# ATBTLC1000WLCSP register map
Vendor: Atmel Corp; Series: SAMB11; File version: TODO
CPU: CM0 r0p0, little endian, no MPU, no FPU, 2 interrupt priority bits
Address unit: 32 bits
Registers are 32-bit, read-write, reset 0x0 unless marked. A register's access mark holds for its fields unless they carry their own. Offsets are from the block's base; [hi:lo] are bit positions; {n}, {i} and the like mark numbered series; 'fields as' and 'values as' point back to an identical list.

## SPI_FLASH0 — SPI Flash Controller
Base 0x40012000
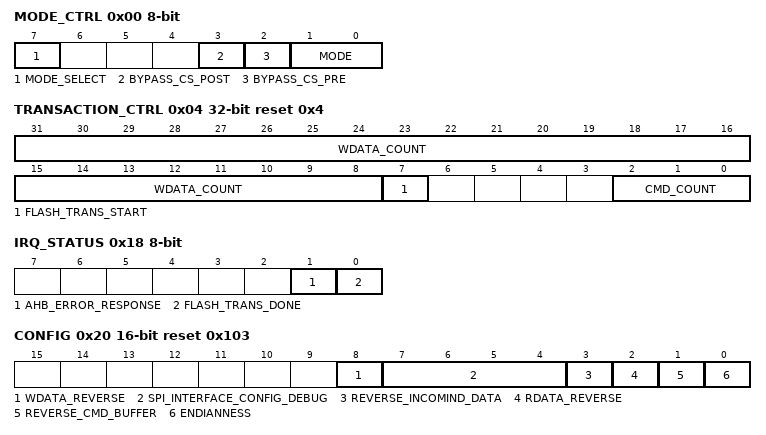
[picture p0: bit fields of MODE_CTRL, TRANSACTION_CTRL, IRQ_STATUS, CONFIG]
0x00 MODE_CTRL 8-bit — SPI Flash Mode Control
  [7] MODE_SELECT — Set to 1 to use external bits for mode
  [3] BYPASS_CS_POST — Bypass CS POST state
  [2] BYPASS_CS_PRE — Bypass CS PRE state
  [1:0] MODE — SPI Modes
    {v}=Mode {v} (v=0..3)
0x04 TRANSACTION_CTRL reset 0x4 — Transaction Control (Cleared after each transaction completes)
  [31:8] WDATA_COUNT — Number of bytes to be programmed to flash
  [7] FLASH_TRANS_START — Rising Edge Flast Transaction Start
  [2:0] CMD_COUNT — Number of bytes to be transferred or received
0x08 READ_CTRL — Read Control (Cleared after each transaction completes)
  [23:0] RDATA_COUNT — Number of data bytes to be read from flash
0x0C CMD_BUFFER0 reset 0x3 — Command Buffer 0 (Bytes 3 - 0)
0x10 CMD_BUFFER1 — Command Buffer 1 (Bytes 7 - 4)
0x14 DIRECTION 8-bit reset 0xF — Read/Write bit for Bytes 7 - 0
0x18 IRQ_STATUS 8-bit wo — IRQ Status (Write 0 to bit to clear, Read clears interupts)
  [1] AHB_ERROR_RESPONSE
  [0] FLASH_TRANS_DONE — Current Flash Transaction Done
0x1C DMA_START_ADDRESS — DMA Starting Address
0x20 CONFIG 16-bit reset 0x103 — SPI Flash Configuration
  [8] WDATA_REVERSE — Reverse bits of every data byte written to flash
  [7:4] SPI_INTERFACE_CONFIG_DEBUG — Debug only
  [3] REVERSE_INCOMIND_DATA — Reverse bits of status registers read from flash
  [2] RDATA_REVERSE — Reverse bits of every data byte read from flash
  [1] REVERSE_CMD_BUFFER — Reverse bits of every byte in cmd_buffer
  [0] ENDIANNESS — 1 for Little Endian
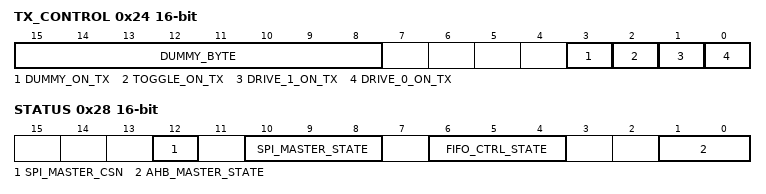
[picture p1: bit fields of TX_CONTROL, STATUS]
0x24 TX_CONTROL 16-bit
  [15:8] DUMMY_BYTE — Byte to be sent for dummy_on_tx option
  [3] DUMMY_ON_TX — Send dummy_byte while reading
  [2] TOGGLE_ON_TX — Toggle TX while reading
  [1] DRIVE_1_ON_TX — Drive 1 on TX while reading
  [0] DRIVE_0_ON_TX — Drive 0 on TX while reading
0x28 STATUS 16-bit ro — Misc Status
  [12] SPI_MASTER_CSN — Inverted version of the SPI Master Chip Select
  [10:8] SPI_MASTER_STATE
    0=IDLE; 1=READ; 2=WRITE; 3=READ_FLASH; 4=WRITE_FLASH; 5=PRE_ACTION; 6=POST_ACTION; 7=WAIT_AHB
  [6:4] FIFO_CTRL_STATE — FIFO Control State
    0=FLASH_IDLE; 1=GET_DATA_FROM_FLASH; 2=WRITE_DATA_TO_AHB; 3=GET_DATA_FROM_AHB; 4=WRITE_DATA_TO_FLASH
  [1:0] AHB_MASTER_STATE
    0=IDLE; 1=WAIT_GRANT; 2=ADDR_PHASE; 3=DATA_PHASE

## ARM_BPU0 — ARM Breakpoint Control
Base 0xE0002000
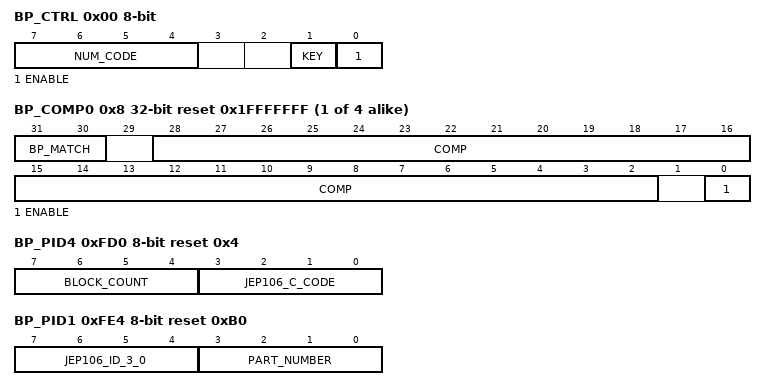
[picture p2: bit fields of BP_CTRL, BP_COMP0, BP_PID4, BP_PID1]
0x00 BP_CTRL 8-bit — Break Point Control Register
  [7:4] NUM_CODE ro — Number of breakpoint comparators
  [1] KEY — Must Write this bit to a 1 for register write to be accepted
  [0] ENABLE — BPU is Enabled
{0x8+4i} BP_COMP{i} reset 0x1FFFFFFF (i=0..3) — Break Point Compare Register {i}
  [31:30] BP_MATCH — Behavior when the COMP address is matched
    0=No Breakpoint Matching; 1=Breakpoint on lower halfword; 2=Breakpoint on upper halfword; 3=Breakpoint on both halfwords
  [28:2] COMP — Bits 28:2 of the comparison address
  [0] ENABLE — Comparator is enabled
0xFD0 BP_PID4 8-bit ro reset 0x4 — Peripheral ID Register 4
  [7:4] BLOCK_COUNT, [3:0] JEP106_C_CODE
0xFE0 BP_PID0 8-bit ro reset 0xB — Peripheral ID Register 0
  [7:0] PART_NUMBER — Part Number Bits 7:0
0xFE4 BP_PID1 8-bit ro reset 0xB0 — Peripheral ID Register 1
  [7:4] JEP106_ID_3_0 — JEP106 ID Code Bits 3:0
  [3:0] PART_NUMBER — Part Number Bits 11:8
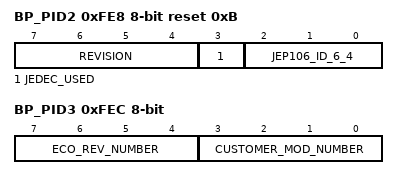
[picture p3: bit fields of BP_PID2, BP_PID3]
0xFE8 BP_PID2 8-bit ro reset 0xB — Peripheral ID Register 2
  [7:4] REVISION
  [3] JEDEC_USED
  [2:0] JEP106_ID_6_4 — JEP106 ID Code Bits 6:4
0xFEC BP_PID3 8-bit ro — Peripheral ID Register 3
  [7:4] ECO_REV_NUMBER — ECO Revision Number
  [3:0] CUSTOMER_MOD_NUMBER — Customer Modification Number
0xFF0 BP_CID0 8-bit ro reset 0xD — Component ID Register 0
0xFF4 BP_CID1 8-bit ro reset 0xE0 — Component ID Register 1
0xFF8 BP_CID2 8-bit ro reset 0x5 — Component ID Register 2
0xFFC BP_CID3 8-bit ro reset 0xB1 — Component ID Register 3

## ARM_DWT0 — ARM DWT Control
Base 0xE0001000
0x00 DWT_CTRL ro — Control Register
  [31:28] NUMCOMP — Number of comparators available
0x1C DWT_PCSR ro — Program Counter Sample Register
  [31:0] EIASAMPLE — Executed Instruction Address sample value
0x20 DWT_COMP0 — DWT Compare Register 0
  [31:0] COMP — Reference Value for Comparison
0x24 DWT_MASK0 8-bit — DWT Mask Register 0
  [4:0] MASK_VALUE — Size of the ignore mask applied to address range matching
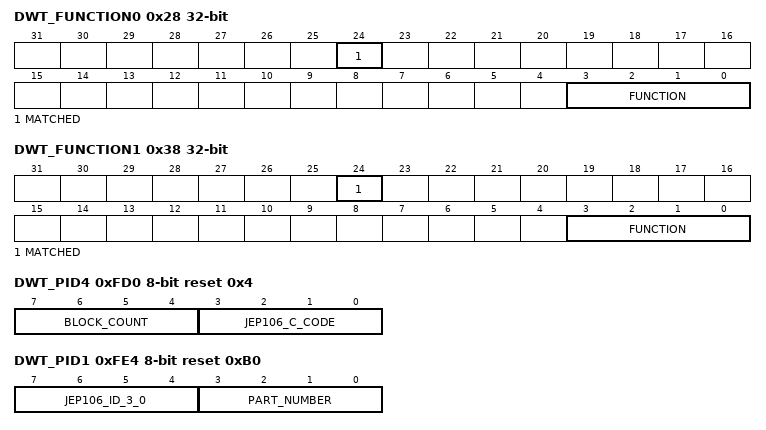
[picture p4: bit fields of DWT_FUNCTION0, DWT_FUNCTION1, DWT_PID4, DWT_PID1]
0x28 DWT_FUNCTION0 ro — DWT Function Register 0
  [24] MATCHED — Comparator Match
  [3:0] FUNCTION rw — Select action on comparator match
    0=Disabled; 4=PC Watchpoint Event (Instruction); 5=Watchpoint Event Read Only (Data); 6=Watchpoint Event Write Only (Data); 7=Watchpoing Event Write-Read (Data)
0x30 DWT_COMP1 — DWT Compare Register 1
  [31:0] COMP — Reference Value for Comparison
0x34 DWT_MASK1 8-bit — DWT Mask Register 1
  fields as DWT_MASK0
0x38 DWT_FUNCTION1 ro — DWT Function Register 1
  fields as DWT_FUNCTION0
0xFD0 DWT_PID4 8-bit ro reset 0x4 — Peripheral ID Register 4
  [7:4] BLOCK_COUNT, [3:0] JEP106_C_CODE
0xFE0 DWT_PID0 8-bit ro reset 0xA — Peripheral ID Register 0
  [7:0] PART_NUMBER — Part Number Bits 7:0
0xFE4 DWT_PID1 8-bit ro reset 0xB0 — Peripheral ID Register 1
  [7:4] JEP106_ID_3_0 — JEP106 ID Code Bits 3:0
  [3:0] PART_NUMBER — Part Number Bits 11:8
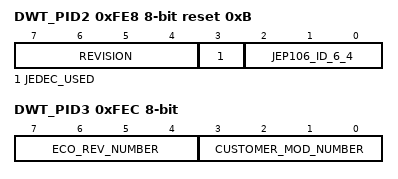
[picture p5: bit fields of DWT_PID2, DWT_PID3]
0xFE8 DWT_PID2 8-bit ro reset 0xB — Peripheral ID Register 2
  [7:4] REVISION
  [3] JEDEC_USED
  [2:0] JEP106_ID_6_4 — JEP106 ID Code Bits 6:4
0xFEC DWT_PID3 8-bit ro — Peripheral ID Register 3
  [7:4] ECO_REV_NUMBER — ECO Revision Number
  [3:0] CUSTOMER_MOD_NUMBER — Customer Modification Number
0xFF0 DWT_CID0 8-bit ro reset 0xD — Component ID Register 0
0xFF4 DWT_CID1 8-bit ro reset 0xE0 — Component ID Register 1
0xFF8 DWT_CID2 8-bit ro reset 0x5 — Component ID Register 2
0xFFC DWT_CID3 8-bit ro reset 0xB1 — Component ID Register 3

## ARM_ROM0 — ARM ROM
Base 0xE00FF000
0x00 ROM_SCS ro reset 0xFFF0F003 — Points to the SCS at 0xE000E000
0x10 ROM_DWT ro reset 0xFFF02003 — Points to the DWT at 0xE0001000
0x20 ROM_BPU ro reset 0xFFF03003 — Points to the BPU at 0xE0002000
0x30 ROM_EOT ro — End of Table Marker
0xFCC ROM_CSMT 8-bit ro reset 0x1 (reset mask 0x1) — System Memory accessible through DAP
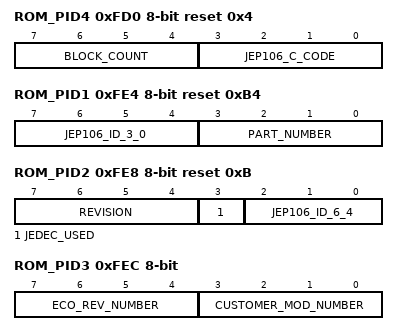
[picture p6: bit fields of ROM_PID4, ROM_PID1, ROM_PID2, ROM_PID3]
0xFD0 ROM_PID4 8-bit ro reset 0x4 — Peripheral ID Register 4
  [7:4] BLOCK_COUNT, [3:0] JEP106_C_CODE
0xFE0 ROM_PID0 8-bit ro reset 0x71 — Peripheral ID Register 0
  [7:0] PART_NUMBER — Part Number Bits 7:0
0xFE4 ROM_PID1 8-bit ro reset 0xB4 — Peripheral ID Register 1
  [7:4] JEP106_ID_3_0 — JEP106 ID Code Bits 6:4
  [3:0] PART_NUMBER — Part Number Bits 11:8
0xFE8 ROM_PID2 8-bit ro reset 0xB — Peripheral ID Register 2
  [7:4] REVISION
  [3] JEDEC_USED
  [2:0] JEP106_ID_6_4 — JEP106 ID Code Bits 6:4
0xFEC ROM_PID3 8-bit ro — Peripheral ID Register 3
  [7:4] ECO_REV_NUMBER — ECO Revision Number
  [3:0] CUSTOMER_MOD_NUMBER — Customer Modification Number
0xFF0 ROM_CID0 8-bit ro reset 0xD — Component ID Register 0
0xFF4 ROM_CID1 8-bit ro reset 0x10 — Component ID Register 1
0xFF8 ROM_CID2 8-bit ro reset 0x5 — Component ID Register 2
0xFFC ROM_CID3 8-bit ro reset 0xB1 — Component ID Register 3
